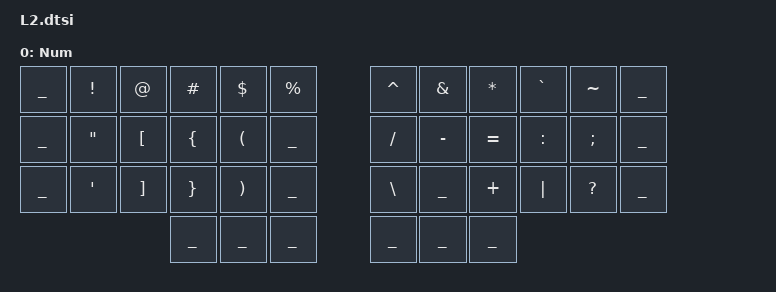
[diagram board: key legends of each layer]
/ {
    keymap {
        compatible = "zmk,keymap";

        Number {
            label = "Num";
            bindings = <
        // ╭──────────┬──────────┬──────────┬──────────┬──────────┬──────────╮   ╭──────────┬──────────┬──────────┬──────────┬──────────┬──────────╮
        // │          │  !       │  @       │  #       │  $       │  %       │   │  ^       │  &       │  *       │  `       │  ~       │          │
              ___     &kp EXCL   &kp AT     &kp HASH   &kp DLLR   &kp PRCNT      &kp CARET  &kp AMPS   &kp ASTRK  &kp GRAVE   &kp TILDE    ___
        // ├──────────┼──────────┼──────────┼──────────┼──────────┼──────────┤   ├──────────┼──────────┼──────────┼──────────┼──────────┼──────────┤
        // │          │  "       │  [       │  {       │  (       │          │   │   /      │  -       │  =       │     :    │  ;       │          │
              ___     &kp DQT    &kp LBKT   &kp LBRC   &kp LPAR      ___         &kp FSLH   &kp MINUS  &kp EQUAL  &kp COLON  &kp SEMI      ___
        // ├──────────┼──────────┼──────────┼──────────┼──────────┼──────────┤   ├──────────┼──────────┼──────────┼──────────┼──────────┼──────────┤
        // │          │  '       │  ]       │  }       │  )       │          │   │    \     │  _       │  +       │  │       │   ?      │          │
              ___     &kp SQT    &kp RBKT   &kp RBRC   &kp RPAR      ___         &kp BSLH   &kp UNDER  &kp PLUS   &kp PIPE  &kp QMARK      ___
        // ╰──────────┴──────────┴──────────┴──────────┼──────────┼──────────┤   ├──────────┼──────────┼──────────┴──────────┴──────────┴──────────╯
                                               ___        ___        ___            ___        ___        ___
        //                                  ╰──────────┴──────────┴──────────╯   ╰──────────┴──────────┴──────────╯
            >;
        };
    };
};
